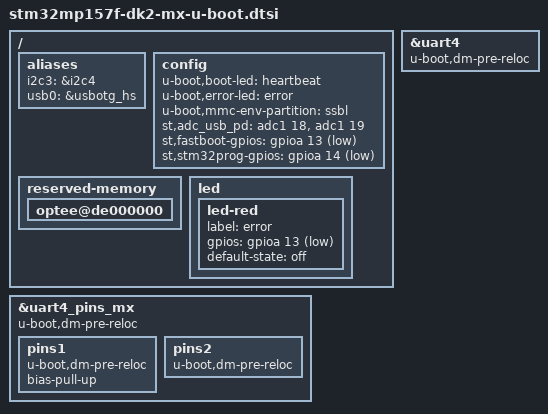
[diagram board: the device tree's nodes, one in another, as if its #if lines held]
/* SPDX-License-Identifier: GPL-2.0+ OR BSD-3-Clause*/
/*
 * Copyright (C) 2022, STMicroelectronics - All Rights Reserved
 * Author: STM32CubeMX code generation for STMicroelectronics.
 */

/* For more information on Device Tree configuration, please refer to
 * https://wiki.st.com/stm32mpu/wiki/Category:Device_tree_configuration
 */

#include "stm32mp15-u-boot.dtsi"

/* USER CODE BEGIN includes */
#include <dt-bindings/clock/stm32mp1-clksrc.h>
/* USER CODE END includes */

/ {

	/* USER CODE BEGIN root */

	aliases{
		i2c3 = &i2c4;
		usb0 = &usbotg_hs;
	};

	config{
		u-boot,boot-led = "heartbeat";
		u-boot,error-led = "error";
		u-boot,mmc-env-partition = "u-boot-env";
		st,adc_usb_pd = <&adc1 18>, <&adc1 19>;
		st,fastboot-gpios = <&gpioa 13 (GPIO_ACTIVE_LOW | GPIO_PULL_UP)>;
		st,stm32prog-gpios = <&gpioa 14 (GPIO_ACTIVE_LOW | GPIO_PULL_UP)>;
	};

#if defined(CONFIG_STM32MP15x_STM32IMAGE) || defined(CONFIG_SPL)

	config{
		u-boot,mmc-env-partition = "ssbl";
	};
#endif

	reserved-memory{
		u-boot,dm-spl;

		optee@de000000{
			u-boot,dm-spl;
		};
	};

	led{

		led-red{
			label = "error";
			gpios = <&gpioa 13 GPIO_ACTIVE_LOW>;
			default-state = "off";
			status = "okay";
		};
	};
	/* USER CODE END root */

}; /*root*/

/* USER CODE BEGIN addons */

&uart4{
	u-boot,dm-pre-reloc;
};

&uart4_pins_mx {
	u-boot,dm-pre-reloc;
	pins1 {	/* UART4_RX */
		u-boot,dm-pre-reloc;
		/* pull-up on rx to avoid floating level */
		bias-pull-up;
	};
	pins2 {
		u-boot,dm-pre-reloc;
	};
};
/* USER CODE END addons */

